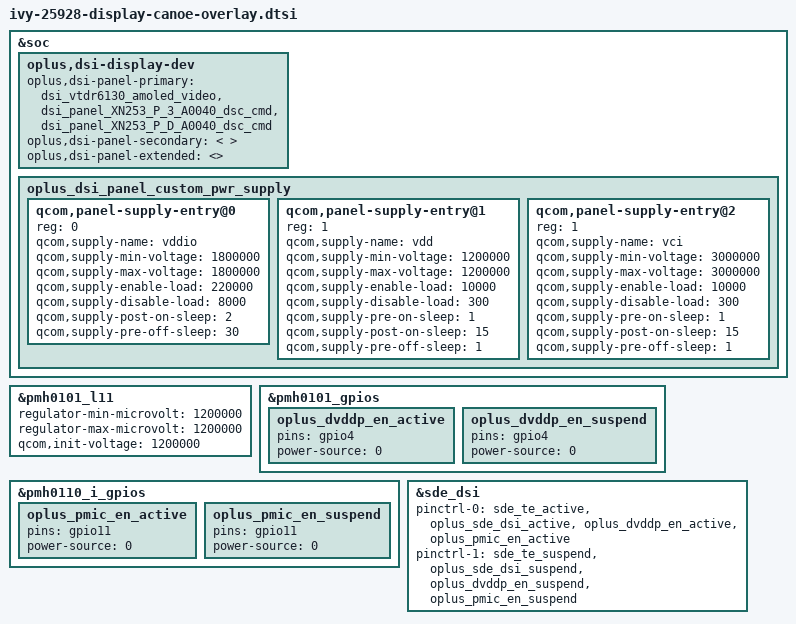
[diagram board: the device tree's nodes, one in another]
#include "panel/dsi-panel-XN253-P-3-A0040-dsc-cmd.dtsi"
#include "panel/dsi-panel-XN253-P-D-A0040-dsc-cmd.dtsi"

&soc {
	oplus,dsi-display-dev {
		oplus,dsi-panel-primary = <
			&dsi_vtdr6130_amoled_video
			&dsi_panel_XN253_P_3_A0040_dsc_cmd
			&dsi_panel_XN253_P_D_A0040_dsc_cmd
		>;
		oplus,dsi-panel-secondary = <
		>;
		oplus,dsi-panel-extended = <>;
	};

	oplus_dsi_panel_custom_pwr_supply: oplus_dsi_panel_custom_pwr_supply {
		#address-cells = <1>;
		#size-cells = <0>;

		qcom,panel-supply-entry@0 {
			reg = <0>;
			qcom,supply-name = "vddio";
			qcom,supply-min-voltage = <1800000>;
			qcom,supply-max-voltage = <1800000>;
			qcom,supply-enable-load = <220000>;
			qcom,supply-disable-load = <8000>;
			qcom,supply-post-on-sleep = <2>;
			qcom,supply-pre-off-sleep = <30>;
		};

		qcom,panel-supply-entry@1 {
			reg = <1>;
			qcom,supply-name = "vdd";
			qcom,supply-min-voltage = <1200000>;
			qcom,supply-max-voltage = <1200000>;
			qcom,supply-enable-load = <10000>;
			qcom,supply-disable-load = <300>;
			qcom,supply-pre-on-sleep = <1>;
			qcom,supply-post-on-sleep = <15>;
			qcom,supply-pre-off-sleep = <1>;
		};

		qcom,panel-supply-entry@2 {
			reg = <1>;
			qcom,supply-name = "vci";
			qcom,supply-min-voltage = <3000000>;
			qcom,supply-max-voltage = <3000000>;
			qcom,supply-enable-load = <10000>;
			qcom,supply-disable-load = <300>;
			qcom,supply-pre-on-sleep = <1>;
			qcom,supply-post-on-sleep = <15>;
			qcom,supply-pre-off-sleep = <1>;
		};
	};
};

&pmh0101_l11 {
	regulator-min-microvolt = <1200000>;
	regulator-max-microvolt = <1200000>;
	qcom,init-voltage = <1200000>;
};

&pmh0101_gpios {
	oplus_dvddp_en_active: oplus_dvddp_en_active {
		pins = "gpio4";
		power-source = <0>; /* 1.8V */

	};

	oplus_dvddp_en_suspend: oplus_dvddp_en_suspend  {
		pins = "gpio4";
		power-source = <0>; /* 1.8V */

	};
};

&pmh0110_i_gpios {
	oplus_pmic_en_active: oplus_pmic_en_active {
		pins = "gpio11";
		power-source = <0>; /* 1.8V */

	};

	oplus_pmic_en_suspend: oplus_pmic_en_suspend  {
		pins = "gpio11";
		power-source = <0>; /* 1.8V */

	};
};

&sde_dsi {
	pinctrl-names = "panel_active", "panel_suspend";
	pinctrl-0 = <&sde_te_active &oplus_sde_dsi_active
				&oplus_dvddp_en_active &oplus_pmic_en_active>;
	pinctrl-1 = <&sde_te_suspend &oplus_sde_dsi_suspend
				&oplus_dvddp_en_suspend &oplus_pmic_en_suspend>;
};
